# SYSCTRL register map
Vendor: Texas Instruments
Peripheral module from a debugger description file (folder UCD3138R032RJA).
Registers are 32-bit, read-write, no defined reset value unless marked. A register's access mark holds for its fields unless they carry their own. Offsets are as the file gives them; lines under a group give offsets from that group; [hi:lo] are bit positions; {n}, {i} and the like mark numbered series; 'fields as' and 'values as' point back to an identical list; <NAME> marks a mode.

## SYSCTRL
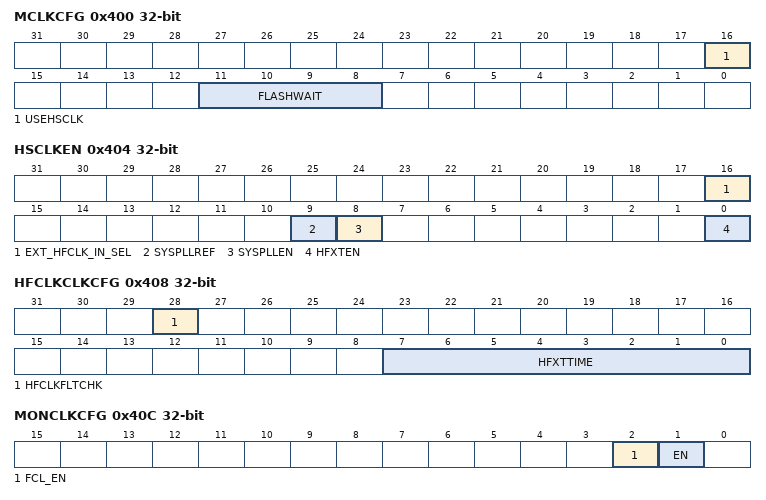
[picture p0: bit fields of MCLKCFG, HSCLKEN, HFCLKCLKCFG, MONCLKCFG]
0x400 MCLKCFG — Configuration related to MCLK
  [16] USEHSCLK — High Speed Clock Selected for MCLK (HFCLK, PLL,...)
    0=DISABLE; 1=ENABLE
  [11:8] FLASHWAIT — Flash wait states when using a high speed clock source - HFCLK or PLL
0x404 HSCLKEN — High Speed Clock Configuration
  [16] EXT_HFCLK_IN_SEL — Use External Pin as High Frequency Oscillator Source(HFCLK)
    0=DISABLE; 1=ENABLE
  [9] SYSPLLREF — System PLL Reference Clock Source 0: SYSOSC, 1:HFCLK
    0=SYSOSC; 1=HFCLK
  [8] SYSPLLEN — Enable the SYSTEM PLL
    0=DISABLE; 1=ENABLE
  [0] HFXTEN — Enable the HFXT Crystal
    0=DISABLE; 1=ENABLE
0x408 HFCLKCLKCFG — High Frequency OSC Clock Configuration
  [28] HFCLKFLTCHK — Check for stuck fault on HFCLK related pins
    0=DISABLE; 1=ENABLE
  [7:0] HFXTTIME — HFXT startup time in 64 usec resolution
0x40C MONCLKCFG — Low Frequency Monitor Clock Configuration
  [2] FCL_EN — FCL enable
    0=DISABLE; 1=ENABLE
  [1] EN — Monitor cloclk enable
    0=DISABLE; 1=ENABLE
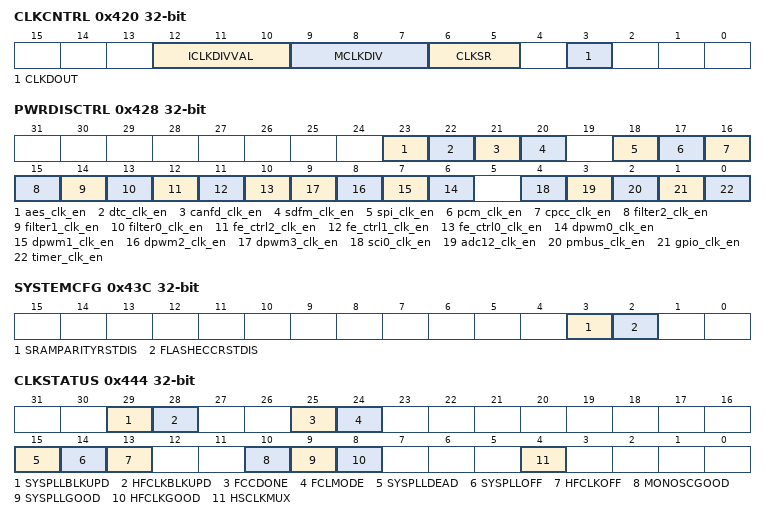
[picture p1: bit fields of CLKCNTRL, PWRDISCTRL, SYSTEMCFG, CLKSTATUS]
0x420 CLKCNTRL — General Clock Configuration
  [12:10] ICLKDIVVAL — ICLK Div ratio
    0=DIV1 (ICLK is MCLK div); 1=DIV2 (ICLK is MCLK div 2); 2=DIV4 (ICLK is MCLK div 4); 3=DIV8 (ICLK is MCLK div 8); 4=DIV16 (ICLK is MCLK div 16); 5=DIV16_X1 (ICLK is MCLK div 16); 6=DIV16_X2 (ICLK is MCLK div 16); 7=DIV16_X3 (ICLK is MCLK div 16)
  [9:7] MCLKDIV — MCLK divide ratio
    0=DIV1 (MCLK is MCLK div); 1=DIV2 (MCLK is MCLK div 2); 2=DIV4 (MCLK is MCLK div 4); 3=DIV8 (MCLK is MCLK div 8); 4=DIV16 (MCLK is MCLK div 16); 5=DIV16_X1 (MCLK is MCLK div 16); 6=DIV32 (MCLK is MCLK div 32); 7=DIV32_X1 (MCLK is MCLK div 32)
  [6:5] CLKSR — These bits control the source/function of CLKOUT
    0=CLKOUT (CLKSR is CLKOUT); 1=ICLK (CLKSR is ICLK); 2=MCLK (CLKSR is MCLK); 3=ICLKDIV4 (CLKSR is ICLK div 4)
  [3] CLKDOUT — This pin represents the output value of CLKOUT
    0=LOWLOGIC; 1=HIGHLOGIC
0x428 PWRDISCTRL — Powe control by CLock enable
  [all] fields
    0=NOTAVAILABLE; 1=AVAILABLE
  [23] aes_clk_en — clock enable
  [22] dtc_clk_en — clock enable
  [21] canfd_clk_en — clock enable
  [20] sdfm_clk_en — clock enable
  [18] spi_clk_en — clock enable
  [17] pcm_clk_en — clock enable
  [16] cpcc_clk_en — clock enable
  [15] filter2_clk_en — clock enable
  [14] filter1_clk_en — clock enable
  [13] filter0_clk_en — clock enable
  [12] fe_ctrl2_clk_en — clock enable
  [11] fe_ctrl1_clk_en — clock enable
  [10] fe_ctrl0_clk_en — clock enable
  [n+6] dpwm{n}_clk_en (n=0..3) — clock enable
  [4] sci0_clk_en — clock enable
  [3] adc12_clk_en — clock enable
  [2] pmbus_clk_en — clock enable
  [1] gpio_clk_en — clock enable
  [0] timer_clk_en — clock enable
0x43C SYSTEMCFG — System configuration for reset
  [3] SRAMPARITYRSTDIS — 0: SRAM Parity Double Error will issue System Reset 1: Reset is disable but sysstatus will be provided (default)
    0=FALSE; 1=TRUE
  [2] FLASHECCRSTDIS — 0: Flash ECC Double Error will issue System Reset 1: Reset is disable but sysstatus will be provided (default)
    0=FALSE; 1=TRUE
0x440 WRITELOCK — SYSOSC Trim Values specified by user
  [0] ACTIVE — LOCK configuration MMRs from write
    0=ENABLE (Allow Writes to Lockable MMRs); 1=DISABLE (Disallow Writes to Lockable MMRs)
0x444 CLKSTATUS ro — Useful debug status of clock selections
  [29] SYSPLLBLKUPD — Writes to SYSPLLCFG0-1, SYSPLLPARAM0-1 are blocked
    0=FALSE; 1=TRUE
  [28] HFCLKBLKUPD — Writes to HFCLKCLKCFG are blocked
    0=FALSE; 1=TRUE
  [25] FCCDONE — SYSOSC FCC DONE
    0=DISABLED; 1=ENABLED
  [24] FCLMODE — SYSOSC FCL MODE ON
    0=DISABLED; 1=ENABLED
  [15] SYSPLLDEAD — SYSPLLDEAD is set by hardware if the selected source for HSCLK was started but did not start successfully.
    0=FALSE (The HSCLK source was not started or started correctly); 1=TRUE (The HSCLK source did not start correctly)
  [14] SYSPLLOFF — SYSPLL is OFF or DEAD
    0=FALSE; 1=TRUE
  [13] HFCLKOFF — HFCLKs is OFF or DEAD
    0=FALSE; 1=TRUE
  [10] MONOSCGOOD — MONOSC ON
    0=FALSE; 1=TRUE
  [9] SYSPLLGOOD — SYSTEM PLL ON
    0=FALSE; 1=TRUE
  [8] HFCLKGOOD — High Frequency Clock ON
    0=FALSE; 1=TRUE
  [4] HSCLKMUX — High Speed Clock Selected for MCLK (HFCLK, PLL,...)
    0=SYSOSC; 1=HSCLK
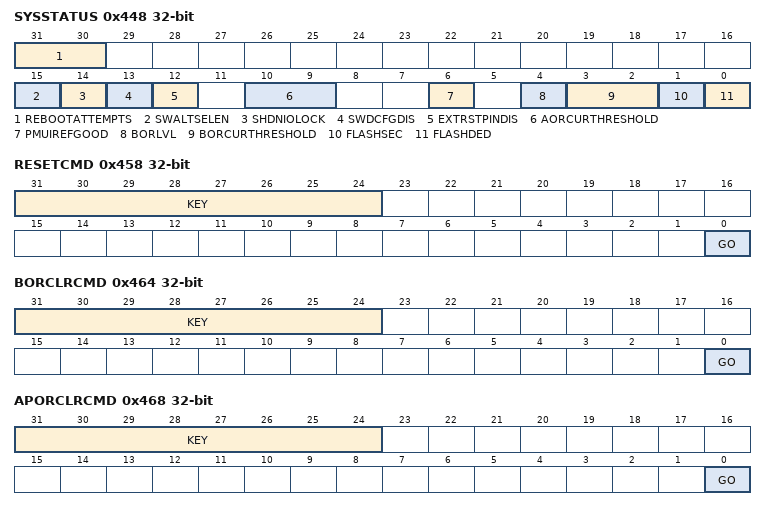
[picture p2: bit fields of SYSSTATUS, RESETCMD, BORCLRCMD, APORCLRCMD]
0x448 SYSSTATUS ro — Useful System Status Data
  [31:30] REBOOTATTEMPTS — REBOOTATTEMPTS indicates the number of boot attempts taken before the user application starts.
  [15] SWALTSELEN — SWD alternate pin selection
    0=FALSE; 1=TRUE
  [14] SHDNIOLOCK — SHDNIOLOCK indicates when IO is locked due to SHUTDOWN
    0=FALSE (IO IS NOT Locked due to SHUTDOWN); 1=TRUE (IO IS Locked due to SHUTDOWN)
  [13] SWDCFGDIS — SWDCFGDIS indicates when user has disabled the use of SWD Port
    0=FALSE (SWD Port Enabled); 1=TRUE (SWD Port Disabled)
  [12] EXTRSTPINDIS — External reset pin disable status
    0=FALSE; 1=TRUE
  [10:9] AORCURTHRESHOLD — APORCURTHRESHOLD indicates the active APOR reset supply monitor configuration.
    0=APORMIN (Default minimum threshold; a APOR0- violation triggers a APOR); 1=APORLEVEL1 (A APOR1- violation generates a APORLVL interrupt); 2=APORLEVEL2 (A APOR2- violation generates a APORLVL interrupt); 3=APORLEVEL3 (A APOR3- violation generates a APORLVL interrupt)
  [6] PMUIREFGOOD — PMU IFREF GOOD
    0=FALSE; 1=TRUE
  [4] BORLVL — BOR LEVEL STATUS Indicator
    0=FALSE; 1=TRUE
  [3:2] BORCURTHRESHOLD — BORCURTHRESHOLD indicates the active brown-out reset supply monitor configuration.
    0=BORMIN (Default minimum threshold; a BOR0- violation triggers a BOR); 1=BORLEVEL1 (A BOR1- violation generates a BORLVL interrupt); 2=BORLEVEL2 (A BOR2- violation generates a BORLVL interrupt); 3=BORLEVEL3 (A BOR3- violation generates a BORLVL interrupt)
  [1] FLASHSEC — Single Error Correction on Flash
    0=FALSE; 1=TRUE
  [0] FLASHDED — Double Error Detect on Flash
    0=FALSE; 1=TRUE
0x44C DEDERRADDR ro — Memory DED Address
  [31:0] ADDR — Address of MEMORY DED Error.
0x450 RSTCAUSE ro — Reset cause
  [4:0] ID — ID is a read-to-clear field which indicates the lowest level reset cause since the last read.
    0=NORST (No reset since last read); 1=PORHWFAIL (POR- violation, SHUTDNSTOREx or PMU trim parity fault); 2=REFCLKFAIL; 3=PORSW (Software triggered POR); 4=BORSUPPLY (BOR0- violation); 8=BOOTNONPMUPARITY (Non-PMU trim parity fault); 9=BOOTCLKFAIL (PLL Fatal clock failure); 12=BOOTEXNRST (NRST triggered BOOTRST (<1s hold)); 13=BOOTSW (Software triggered BOOTRST); 16=FLASHDED; 17=SRAMDED; 18=CPULOCK (CPU lock up condition); 19=DEBUGSS (DebugSS reset); 20=CPURESET; 21=ILLEGAL (ILLEGAL ACCESS)
0x454 RESETLEVEL — Reset level for application-triggered reset command
  [2:0] LEVEL — LEVEL is used to specify the type of reset to be issued when RESETCMD is set to generate a software triggered reset.
    1=BOOT (Issue a BOOTRST (CPU, peripherals, and boot configuration routine)); 3=POR (Issue a power-on reset (POR))
0x458 RESETCMD wo — Execute Reset Command
  [31:24] KEY — Must have KEY==0xE4(228) for write
    228=VALUE (Issue Reset)
  [0] GO — Execute Reset defined in RESETLEVEL
    1=TRUE (Issue Reset)
0x45C BORRSTDIS — BOR Reset Disable register
  [31] RSTDISABLE — BORRSTDIS specifies whether a BOR Event will trigger a BOR Reset or not.
    0=BORNRST (BOR Event will not Trigger a BOR RST); 0=BORRST (BOR Event will Trigger a BOR RST)
0x464 BORCLRCMD wo — Set the BOR threshold
  [31:24] KEY — The key value of C7h (199) must be written to KEY together with GO to trigger the clear and BOR threshold change.
    199=VALUE (Issue clear)
  [0] GO — GO clears any prior BOR violation status indications and attempts to change the active BOR mode to that specified in the LEVEL field of the BORTHRESHOLD register.
    1=TRUE (Issue clear)
0x468 APORCLRCMD wo — Set the APOR threshold
  [31:24] KEY — The key value of C8h (199) must be written to KEY together with GO to trigger the clear and APOR threshold change.
    200=VALUE (Issue clear)
  [0] GO — GO clears any prior APOR violation status indications and attempts to change the active APOR mode to that specified in the LEVEL field of the APORTHRESHOLD register.
    1=TRUE (Issue clear)
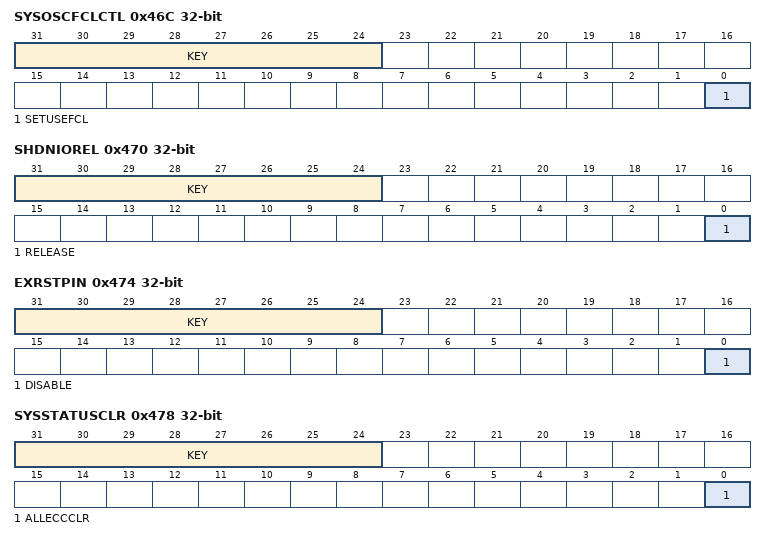
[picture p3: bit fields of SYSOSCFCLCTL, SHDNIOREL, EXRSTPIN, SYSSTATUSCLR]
0x46C SYSOSCFCLCTL wo — SYSOSC Frequency Control Loop with External Resistor
  [31:24] KEY — Must have KEY==0x2A(42) for write
    42=VALUE (Issue Command)
  [0] SETUSEFCL — Use Freq Control Loop
    1=TRUE (Set FCL Control)
0x470 SHDNIOREL wo — Shutdown IO Release Command
  [31:24] KEY — Must have KEY==0x4F(79) for write
    79=VALUE (Issue Command)
  [0] RELEASE — Release IO after Shutdown
    1=TRUE (Release IO after SHUTDOWN Exit)
0x474 EXRSTPIN wo — Disable use of external Reset Pin
  [31:24] KEY — Must have KEY==0x1E(30) for write
    30=VALUE (Issue Command)
  [0] DISABLE — Disable External Reset
    0=FALSE; 1=TRUE (Disable External Reset)
0x478 SYSSTATUSCLR wo — Clear sticky bits of SYSSTATUS
  [31:24] KEY — Must have KEY==0xCE(206) for write
    206=VALUE (Issue Command)
  [0] ALLECCCLR — Clear ALL ECC related SYSSTATUS indicators
    1=CLEAR (Clear ECC state)
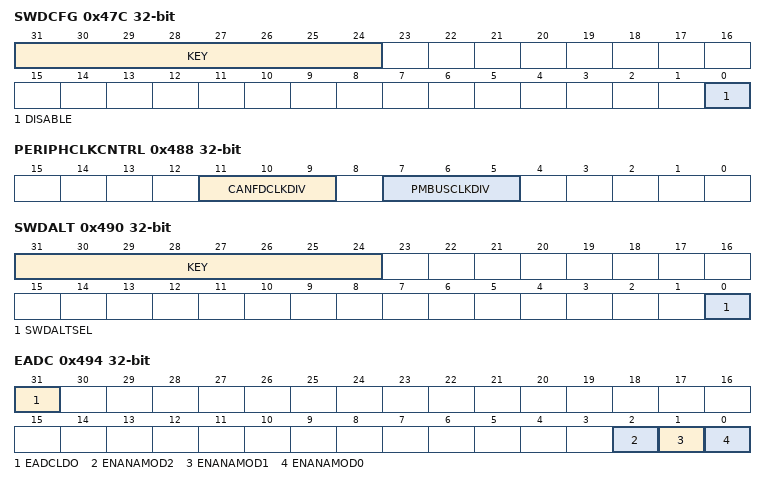
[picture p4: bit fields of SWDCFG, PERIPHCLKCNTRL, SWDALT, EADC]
0x47C SWDCFG wo — Disable SWD
  [31:24] KEY — Must have KEY==0x62(98) for write
    98=VALUE (Issue Command)
  [0] DISABLE — Set DISABLE to disable the SWD function on SWD pins, allowing the SWD pins to be used as GPIO.
    1=TRUE (Disable SWD function on SWD pins)
0x488 PERIPHCLKCNTRL — Peripheral Clock Configuration
  [11:9] CANFDCLKDIV — CANFD Clock divide ratio
    0=DIV1 (Divide ICLK by 1); 1=DIV2 (Divide ICLK by 2); 2=DIV4 (Divide ICLK by 4); 3=DIV8 (Divide ICLK by 8); 4=DIV16 (Divide ICLK by 8); 5=DIV16_X1 (Divide ICLK by 8); 6=DIV32 (Divide ICLK by 8); 7=DIV32_X1 (Divide ICLK by 8)
  [7:5] PMBUSCLKDIV — PMBUS Clock divide ratio
    values as CANFDCLKDIV
0x48C PCLKPRESCALER
  [0] PCLK_PRESCALER_DIVVAL — This determines the division value for PCLK
    0=DIV_BY_1; 1=DIV_BY_2
0x490 SWDALT wo — SWD Alternate pin selection
  [31:24] KEY — Must have KEY==0x62(98) for write
    98=VALUE (Issue Command)
  [0] SWDALTSEL — Alternal pin selection for SWDIO
    0=FALSE (PAD14 is SWDIO); 1=TRUE (PAD16 is SWDIO)
0x494 EADC — EADC control pins
  [31] EADCLDO — EADC LDO disdable pin
    1=TRUE (Disable the ADC LDO); 0=FALSE (Not disable the ADC LDO)
  [2] ENANAMOD2 — EADC EN anamod inst 2
    1=TRUE (Enable the ANAMOD 2); 0=FALSE (Disable the ANAMOD 2)
  [1] ENANAMOD1 — EADC EN anamod inst 1
    1=TRUE (Enable the ANAMOD 1); 0=FALSE (Disable the ANAMOD 1)
  [0] ENANAMOD0 — EADC EN anamod inst 0
    1=TRUE (Enable the ANAMOD 0); 0=FALSE (Disable the ANAMOD 0)
0x800 LIFECYCLE — Device Lifecycle
  [7:0] VALUE — Device Lifecycle set by BOOTCODE READY=0x69(105), ATTEST=0x55(85), PREPROBE=0x96(150)
    105=PREPROBE (Device in Pre Probe State); 150=READY (Device in Product Mode); 85=ATTEST (Device in TI Test Mode)
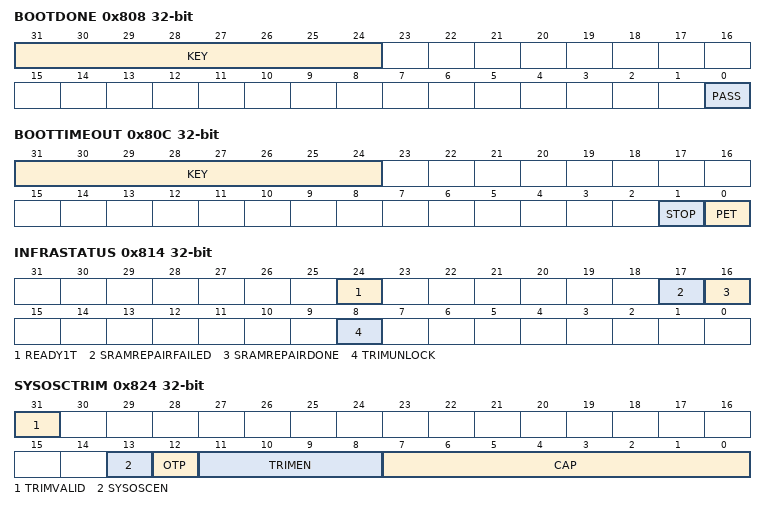
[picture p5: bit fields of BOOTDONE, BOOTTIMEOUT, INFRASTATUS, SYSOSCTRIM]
0x808 BOOTDONE wo — BOOTCODE PASS
  [31:24] KEY — Must have KEY==0xCA(202) for write
    202=VALUE (Issue Reset)
  [0] PASS — BOOTCODE writes 1 for PASS, left unwritten a timeout will occur if not blocked
    1=TRUE (BOOTCODE PASS)
0x80C BOOTTIMEOUT wo — BOOT TIMEOUT Control
  [31:24] KEY — Must have KEY==0x35(53) for write
    53=VALUE (Issue Reset)
  [1] STOP — BOOTCODE writes 1 for STOPPING BOOT TIMEOUT Counter
    1=TRUE (STOP Bootcode Timeout Counter)
  [0] PET — BOOTCODE writes 1 for reloading BOOT TIMEOUT Counter
    1=TRUE (Restart Bootcode Timeout Counter)
0x810 BCTRIMUNLOCK wo — BootCode TRIM Unlock
  [31:0] KEY — BootCode TRIM Unlock Signiture: 0xE1BE41F1
    0xE1BE41F1=VALUE (Issue Reset)
0x814 INFRASTATUS ro — Infrastructure Status
  [24] READY1T — Flash 1T Read mode is available
  [17] SRAMREPAIRFAILED — SRAM repair has failed
  [16] SRAMREPAIRDONE — SRAM repair is completed or not supported on this SOC
  [8] TRIMUNLOCK — TRIM MMRs are UNLOCKED
0x818 BOOTDIAG — 32 bit boot diagnostic to Debugss
  [31:0] BOOTSTATUS
0x81C INFRASTATUS1 ro — Infrastructure Status 2
  [0] CRPAD — Customer Return Pad
0x820 JTAGUSERCODE
  [31:0] DATA — JTAG USERCODE for Debugger
0x824 SYSOSCTRIM — SYSOSC Trim Values for frequency when change from disable to enable, generally 32MHz
  [31] TRIMVALID — TRIM Data Valid- used to trigger FSM
  [13] SYSOSCEN — SYSOSC enable
  [12] OTP — otp - tie high
  [11:8] TRIMEN — Trim en - tie low
  [7:0] CAP — CAP TRIM - Changes per frequency target
{0x828+4i} PMUTRIM{i} (i=0..6)
  [9:0] DATA — SEE PMU definition for usage
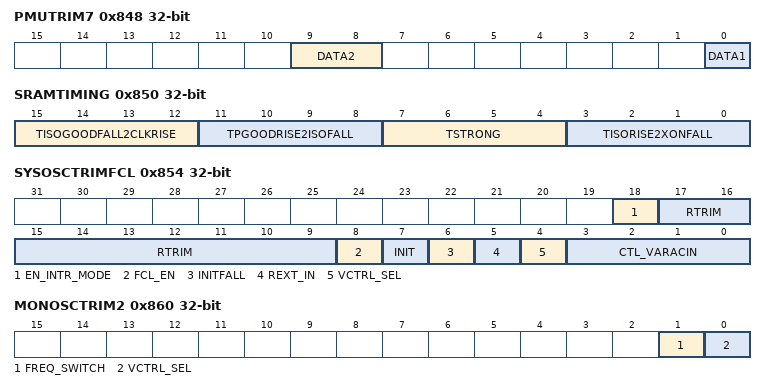
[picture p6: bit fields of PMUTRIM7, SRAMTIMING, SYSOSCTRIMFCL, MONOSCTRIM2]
0x848 PMUTRIM7
  [9:8] DATA2 — SEE PMU definition for usage
  [0] DATA1 — SEE PMU definition for usage
0x84C SRAMREPAIR — $brname sram Repair
  [13:0] DATA — Repair Bits
0x850 SRAMTIMING — SRAM timing MMR for ESRAM controller, based on 4MHz
  [15:12] TISOGOODFALL2CLKRISE — ISO GOOD FALL to CLKRISE, spec 250ns (boot 500ns)
  [11:8] TPGOODRISE2ISOFALL — PGOOD RISE to ISO FALL, spec 750ns (boot 1500ns)
  [7:4] TSTRONG — Driver Weak to Stong timing, spec 1000ns (boot 1500ns)
  [3:0] TISORISE2XONFALL — ISO Rise to any ON FALL, spec 500ns (boot 750ns)
0x854 SYSOSCTRIMFCL — SYSOSC Trim Values for frequency when change from disable to enable, generally 32MHz
  [18] EN_INTR_MODE — 1- enable internal R mode for FCL loop
  [17:9] RTRIM — sysosc Rlad trimming (9bits)
  [8] FCL_EN — 1-enable frequency control loop of sysosc
  [7] INIT — 1- precharge path cutoff when FCL_en=0
  [6] INITFALL — 1- allows to FCL mode to power up only after precharge
  [5] REXT_IN — 1-enable external R mode for FCL loop
  [4] VCTRL_SEL — 1- sets the vctrl from amp instead of divider 0- cuts off Res div when 0
  [3:0] CTL_VARACIN — default-0100 (select varactor bank)
0x858 MONOSCTRIM0 — MONOSC TRIM 1 values
  [31:0] MONCLKTRIM0 — Monitor clock Trim
0x85C MONOSCTRIM1 — MONOSC TRIM 2 values
  [31:0] MONCLKTRIM0 — Monitor clock Trim
0x860 MONOSCTRIM2 — MONOSC TRIM 3 values
  [1] FREQ_SWITCH — Frequency switch
    0=DISABLE; 1=ENABLE
  [0] VCTRL_SEL — Voltage control sel
    0=DISABLE (Voltage control is not selected); 1=Enable (Voltage control is selected)
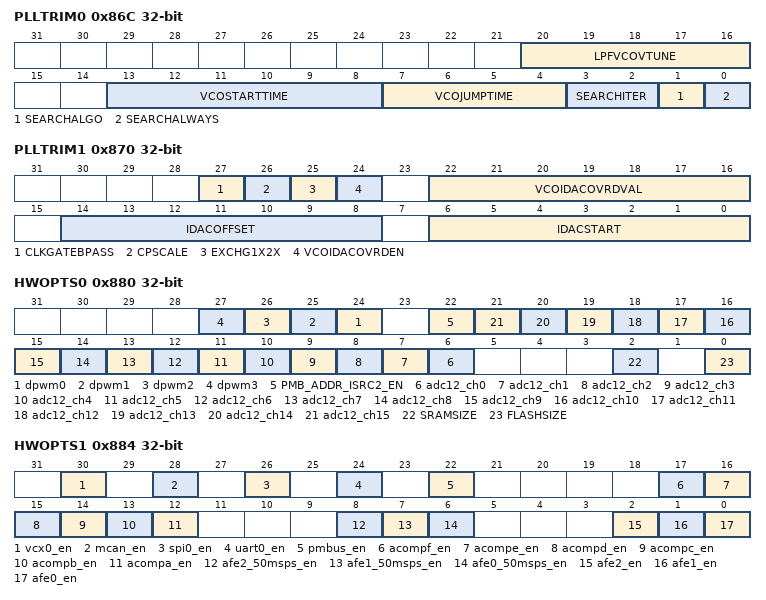
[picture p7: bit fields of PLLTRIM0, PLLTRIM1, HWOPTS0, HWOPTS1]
0x86C PLLTRIM0 — PLL TRIM and Override
  [20:16] LPFVCOVTUNE — LPF VCOVTUNE NOM Value
  [13:8] VCOSTARTTIME — VCO Start Settling Time in SYSOSC BASE clocks generally 32MHz - this comes before STARTTIME-STARTTIMELP
  [7:4] VCOJUMPTIME — VCO Freq Jump Settling Time
  [3:2] SEARCHITER — Search iterations to perform
    0=OneIteration; 1=TwoIteration; 2=ThreeIteration; 3=FourIteration
  [1] SEARCHALGO — Select Search Mode Algorithm
    0=ALG1; 1=ALG2
  [0] SEARCHALWAYS — Force Freq Search to ALWAYS be performed
    0=DISABLE; 1=ENABLE
0x870 PLLTRIM1 — PLL TRIM and Override
  [27] CLKGATEBPASS — Clock Gating Bypass added to SPARE MMR bit 1 port
    0=DISABLE; 1=ENABLE
  [26] CPSCALE — CP Scale added to SPARE MMR bit 0 port
    0=DISABLE; 1=ENABLE
  [25] EXCHG1X2X — Exchange 1X and 2X clock paths - Experimental
    0=DISABLE; 1=ENABLE
  [24] VCOIDACOVRDEN — VCO Feq IDAC mcode override enable
    0=DISABLE; 1=ENABLE
  [22:16] VCOIDACOVRDVAL — VCO Feq IDAC mcode override val
  [14:8] IDACOFFSET — IDAC Offset Value
  [6:0] IDACSTART — IDAC Start Value
0x874 MISCTRIM — Various Small TRIM
  [2:0] PMUSMPLMODE — PMU REF/BOR Sample Periode TRIM for STANDBY Mode
    0=SMPL8MS (Sample Periode is 8ms); 1=SMPL16MS (Sample Periode is 16ms); 2=SMPL32MS (Sample Periode is 32ms); 3=SMPL48MS (Sample Periode is 48ms); 4=SMPL64MS (Sample Periode is 64ms); 5=SMPL80MS (Sample Periode is 80ms); 6=SMPL100MS (Sample Periode is 100ms); 7=SMPL125MS (Sample Periode is 125ms)
0x880 HWOPTS0 — IP Available Paper Spin
  [all] fields
    0=NOTAVAILABLE; 1=AVAILABLE
  [n+24] dpwm{n} (n=0..3) — Peripheral Instance Available
  [22] PMB_ADDR_ISRC2_EN — Peripheral Instance Available
  [n+6] adc12_ch{n} (n=0..15) — Peripheral Instance Available
  [2] SRAMSIZE — Peripheral Instance Available
  [0] FLASHSIZE — Peripheral Instance Available
0x884 HWOPTS1 — IP Available Paper Spin
  [all] fields
    0=NOTAVAILABLE; 1=AVAILABLE
  [30] vcx0_en — Peripheral Instance Available
  [28] mcan_en — Peripheral Instance Available
  [26] spi0_en — Peripheral Instance Available
  [24] uart0_en — Peripheral Instance Available
  [22] pmbus_en — Peripheral Instance Available
  [17] acompf_en — Peripheral Instance Available
  [16] acompe_en — Peripheral Instance Available
  [15] acompd_en — Peripheral Instance Available
  [14] acompc_en — Peripheral Instance Available
  [13] acompb_en — Peripheral Instance Available
  [12] acompa_en — Peripheral Instance Available
  [8] afe2_50msps_en — Peripheral Instance Available
  [7] afe1_50msps_en — Peripheral Instance Available
  [6] afe0_50msps_en — Peripheral Instance Available
  [2] afe2_en — Peripheral Instance Available
  [1] afe1_en — Peripheral Instance Available
  [0] afe0_en — Peripheral Instance Available
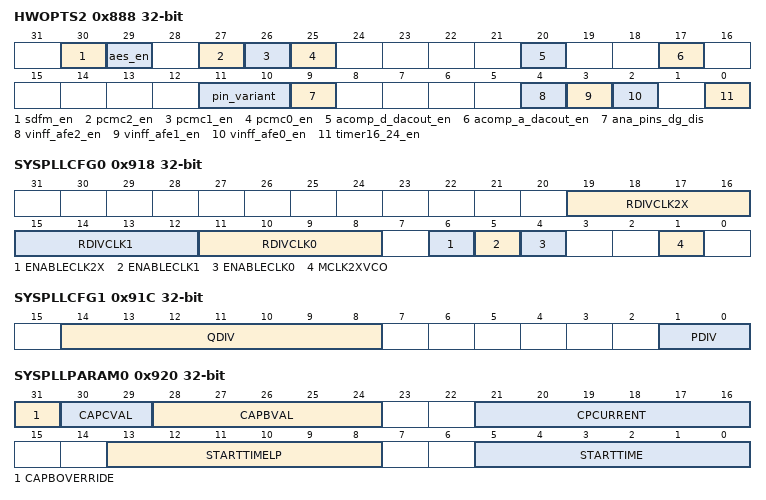
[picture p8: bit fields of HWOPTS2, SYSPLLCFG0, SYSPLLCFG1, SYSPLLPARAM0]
0x888 HWOPTS2 — IP Available Paper Spin
  [30] sdfm_en — Enables SDFM module
    0=Disable_SDFM_Module; 1=Enable_SDFM_Module
  [29] aes_en — Peripheral Instance Available
    0=NOTAVAILABLE; 1=AVAILABLE
  [27] pcmc2_en — Peripheral Instance Available
    0=NOTAVAILABLE; 1=AVAILABLE
  [26] pcmc1_en — Peripheral Instance Available
    0=NOTAVAILABLE; 1=AVAILABLE
  [25] pcmc0_en — Peripheral Instance Available
    0=NOTAVAILABLE; 1=AVAILABLE
  [20] acomp_d_dacout_en — Peripheral Instance Available
    0=NOTAVAILABLE; 1=AVAILABLE
  [17] acomp_a_dacout_en — Peripheral Instance Available
    0=NOTAVAILABLE; 1=AVAILABLE
  [11:10] pin_variant — Controls the pin variant for IO-MUX selections in the IOC controller
    0=Variant24pin; 1=Variant32pin; 3=Variant40pin
  [9] ana_pins_dg_dis — Peripheral Instance Available
    0=NOTAVAILABLE; 1=AVAILABLE
  [4] vinff_afe2_en — Peripheral Instance Available
    0=NOTAVAILABLE; 1=AVAILABLE
  [3] vinff_afe1_en — Peripheral Instance Available
    0=NOTAVAILABLE; 1=AVAILABLE
  [2] vinff_afe0_en — Peripheral Instance Available
    0=NOTAVAILABLE; 1=AVAILABLE
  [0] timer16_24_en — Peripheral Instance Available
    0=NOTAVAILABLE; 1=AVAILABLE
0x88C TRIMCRC — FINAL 16 bit CRC of the TRIM load
  [31:0] DATA — final 16 bit CRC value
0x890 ADCLDOCNTL — ADC LDO control bits
  [14:0] DATA
0x894 ANATOPREG1 — ANATOP Regsiter 1
  [31:0] DATA — Anatop register 1
0x898 ANATOPREG2 — ANATOP Regsiter 2
  [31:0] DATA — Anatop register 2
0x89C CLKTOPREG6 — CLKTOP Regsiter 6
  [31:0] DATA — Clktop register 6
0x910 CLKTOPREG7 — CLKTOP Regsiter 7
  [31:0] DATA — Clktop register 7
0x914 CLKTOPREG8 — CLKTOP Regsiter 8
  [31:0] DATA — Clktop register 8
0x918 SYSPLLCFG0 — System PLL Configuration 0 MMR
  [19:16] RDIVCLK2X — Final Divider for CLK2X Output 1-16
  [15:12] RDIVCLK1 — Final Divider for CLK1 Output 1-16
  [11:8] RDIVCLK0 — Final Divider for CLK0 Output 1-16
  [6] ENABLECLK2X — PLL CLK2X Output enabled
    0=DISABLE; 1=ENABLE
  [5] ENABLECLK1 — PLL CLK1 Output enabled
    0=DISABLE; 1=ENABLE
  [4] ENABLECLK0 — PLL CLK0 Output enabled
    0=DISABLE; 1=ENABLE
  [1] MCLK2XVCO — Use PLL CLK2X PATH as source for MCLK
    0=DISABLE; 1=ENABLE
0x91C SYSPLLCFG1 — System PLL Configuration 1 MMR
  [14:8] QDIV — PLL Feedback Clock Divider 1-127 by 1
  [1:0] PDIV — PLL Reference Clock Divider 1,2,4,8
    0=REFDIV1 (PLL REF CLK is REF CLK); 1=REFDIV2 (PLL REF CLK is REF CLK div 2); 2=REFDIV4 (PLL REF CLK is REF CLK div 4); 3=REFDIV8 (PLL REF CLK is REF CLK div 8)
0x920 SYSPLLPARAM0 — System PLL Paramater 0 MMR --- Data from Flash Table Lookup
  [31] CAPBOVERRIDE — Override Enable For Cap B
    0=DISABLE; 1=ENABLE
  [30:29] CAPCVAL — Override Value for Cap C
  [28:24] CAPBVAL — Override Value for Cap B
  [21:16] CPCURRENT — Charge Pump Current
  [13:8] STARTTIMELP — Startup time from Low Power Exit to Locked Clock in resolution of 1usec
  [5:0] STARTTIME — Startup time from Enable to Locked Clock in resolution of 1usec
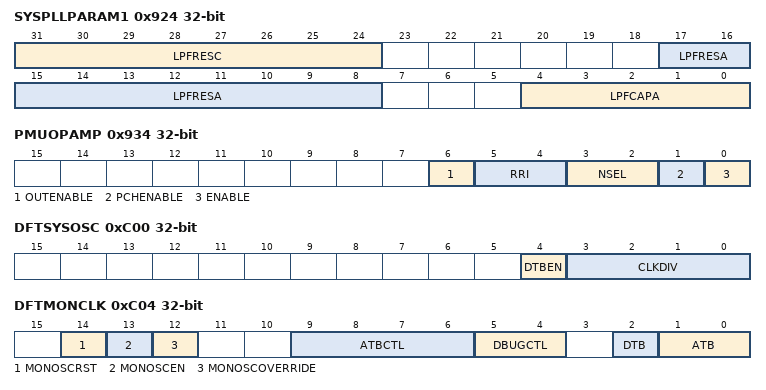
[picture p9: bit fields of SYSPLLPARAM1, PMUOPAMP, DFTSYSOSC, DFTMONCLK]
0x924 SYSPLLPARAM1 — System PLL Paramater 1 MMR --- Data from Flash Table Lookup
  [31:24] LPFRESC — Loop Filter Res C
  [17:8] LPFRESA — Loop Filter Res A
  [4:0] LPFCAPA — Loop Filter Cap A
0x928 LDOCONTROLBITS — DIG LDO control bits
  [4:0] DATA
0x92C APORTHRESHOLD — APOR Threshold Level
  [1:0] LEVEL — APOR Threshold Level 0: Full Re-boot This level is always enforced regardless of MMR seting 1-3: Generates interrupt
    0=APORMIN (Minimum allowed threshold - will force a re-boot); 1=BORLEVEL1 (BOR Level 1 -- Generates an Interupt); 2=APORLEVEL2 (BOR Level 2 -- Generates an Interupt); 3=APORLEVEL3 (BOR Level 3 -- Generates an Interupt)
0x930 BORTHRESHOLD — BOR Threshold Level
  [1:0] LEVEL — BOR Threshold Level 0: Full Re-boot This level is always enforced regardless of MMR seting 1-3: Generates interrupt
    3=BORMIN (Minimum allowed threshold - will force a re-boot)
0x934 PMUOPAMP — PMU OPAMP Control
  [6] OUTENABLE — Output To Pad Enable
    0=FALSE; 1=TRUE
  [5:4] RRI — Rail to Rail Input Mode Select
    0=MODE0 (select PMOS input pairs mode); 1=MODE1 (select NMOS input pairs mode); 2=MODE2 (select rail to rail mode); 3=MODE3 (select sample channel 0)
  [3:2] NSEL — Negative Channel Input Select
    0=SEL0 (Select buf output pad as input); 1=SEL1 (slect unbuf output pad as input); 2=SEL2 (select internal buffer output as input); 3=SEL3 (no channel selected)
  [1] PCHENABLE — Positive Channel Input Enable
    0=FALSE; 1=TRUE
  [0] ENABLE — Enable PMU OPAMP
    0=FALSE; 1=TRUE
0x938 MCANSRAMREPAIR — $brname sram Repair
  [13:0] DATA — Repair Bits
0xC00 DFTSYSOSC — DFT Control for HFXT
  [4] DTBEN — Enable DTB Structure
    0=DISABLE; 1=ENABLE
  [3:0] CLKDIV — Clock Div value for DTB
0xC04 DFTMONCLK — DFT Control for MONCLK Hard Macro
  [14] MONOSCRST — MON OSC reset
  [13] MONOSCEN — MON OSC enable
  [12] MONOSCOVERRIDE — MON OSC enable
  [9:6] ATBCTL — ATB control
  [5:4] DBUGCTL — Debug control
  [2] DTB — DTB enable
    0=DISABLE; 1=ENABLE
  [1:0] ATB — Bit1: enables buffered path, Bit0 enables unbuffered path
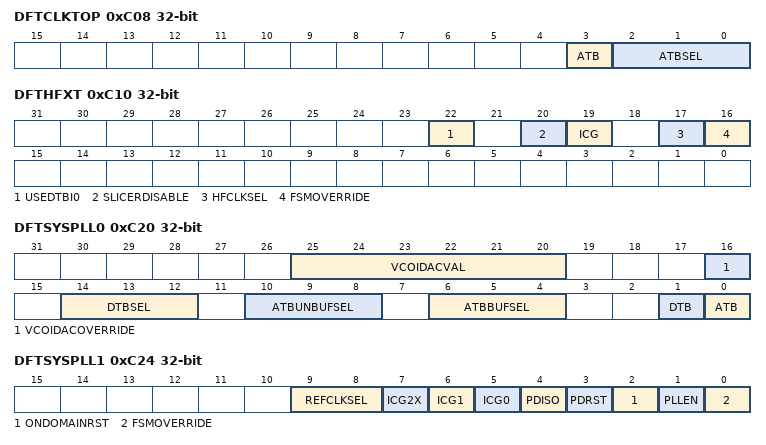
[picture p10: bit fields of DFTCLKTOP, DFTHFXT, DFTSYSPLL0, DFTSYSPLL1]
0xC08 DFTCLKTOP — DFT for CLKTOP to bring voltage reference
  [3] ATB — ATB enable
  [2:0] ATBSEL — ATB Select line
0xC10 DFTHFXT — DFT Control for HFXT
  [22] USEDTBI0 — Use DTBI[0] as the HFCLK output
    0=FALSE; 1=TRUE
  [20] SLICERDISABLE — Turn off slicer
    0=FALSE; 1=TRUE
  [19] ICG — Override Turn HFCLK related ICGs ON qualified with HFCLKSEL
    0=DISABLE; 1=ENABLE
  [17] HFCLKSEL — Use External Pin as High Frequency Oscillator Source(HFCLK)
    0=HFXT; 1=EXTHF
  [16] FSMOVERRIDE — Override outputs of HFCLK FSM
    0=DISABLE; 1=ENABLE
0xC20 DFTSYSPLL0 — DFT Control for SYSPLL
  [25:20] VCOIDACVAL — Override Value For VCO Freq Idac Code
  [16] VCOIDACOVERRIDE — Override Enable For VCO Freq Idac Code
    0=DISABLE; 1=ENABLE
  [14:12] DTBSEL — DTB Signal Select
  [10:8] ATBUNBUFSEL — ATB UnBuffered Signal Select
  [6:4] ATBBUFSEL — ATB Buffered Signal Select
  [1] DTB — Enable DTB Structure
    0=DISABLE; 1=ENABLE
  [0] ATB — Enable ATB Structure
    0=DISABLE; 1=ENABLE
0xC24 DFTSYSPLL1 — DFT Control for SYSPLL
  [9:8] REFCLKSEL — Override value to select Ref Clk
    0=SYSOSC; 1=HFCLK; 2=DTBI0
  [7] ICG2X — Override value to turn PLL ICGCLK2X ON
    0=DISABLE; 1=ENABLE
  [6] ICG1 — Override value to turn PLL ICGCLK1 ON
    0=DISABLE; 1=ENABLE
  [5] ICG0 — Override value to turn PLL ICGCLK0 ON
    0=DISABLE; 1=ENABLE
  [4] PDISO — Assert ISO PD to the hard macro
    0=DEASSERT; 1=ASSERT
  [3] PDRST — Assert RST PD to the hard macro
    0=DEASSERT; 1=ASSERT
  [2] ONDOMAINRST — Assert ONDOMAIN RST to the hard macro
    0=DEASSERT; 1=ASSERT
  [1] PLLEN — Override value for PLL ENABLE to PLL
    0=DISABLE; 1=ENABLE
  [0] FSMOVERRIDE — Override outputs of PLL FSM
    0=DISABLE; 1=ENABLE
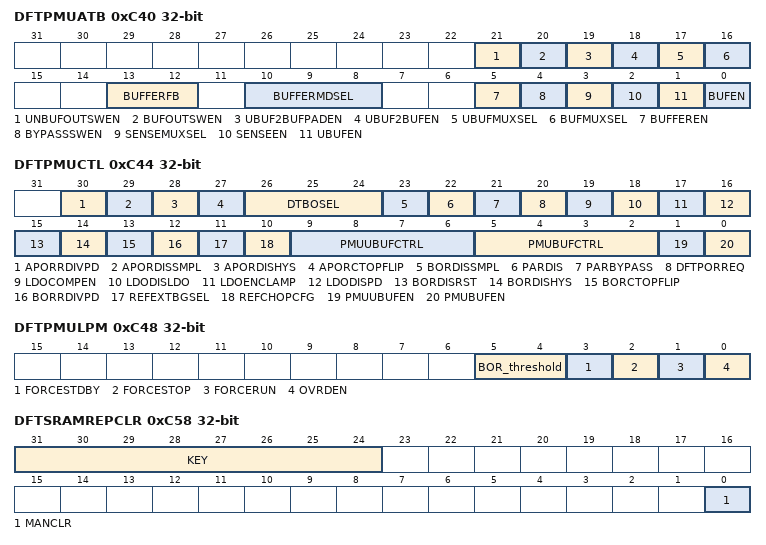
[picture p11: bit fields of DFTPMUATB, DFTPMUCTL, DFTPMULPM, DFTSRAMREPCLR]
0xC40 DFTPMUATB — DFT Control for PMU ATB
  [21] UNBUFOUTSWEN
  [20] BUFOUTSWEN
  [19] UBUF2BUFPADEN
  [18] UBUF2BUFEN
  [17] UBUFMUXSEL
  [16] BUFMUXSEL
  [13:12] BUFFERFB
  [10:8] BUFFERMDSEL
  [5] BUFFEREN
  [4] BYPASSSWEN
  [3] SENSEMUXSEL
  [2] SENSEEN
  [1] UBUFEN — ATB UnBuffered Output Enable
  [0] BUFEN — ATB Buffered Output Enable
0xC44 DFTPMUCTL — DFT Control for PMU CTL
  [30] APORRDIVPD
  [29] APORDISSMPL
  [28] APORDISHYS
  [27] APORCTOPFLIP
  [26:24] DTBOSEL
  [23] BORDISSMPL
  [22] PARDIS
  [21] PARBYPASS
  [20] DFTPORREQ
  [19] LDOCOMPEN
  [18] LDODISLDO
  [17] LDOENCLAMP
  [16] LDODISPD
  [15] BORDISRST
  [14] BORDISHYS
  [13] BORCTOPFLIP
  [12] BORRDIVPD
  [11] REFEXTBGSEL
  [10] REFCHOPCFG
  [9:6] PMUUBUFCTRL
  [5:2] PMUBUFCTRL
  [1] PMUUBUFEN — ATB UnBuffered Output Enable
  [0] PMUBUFEN — ATB Buffered Output Enable
0xC48 DFTPMULPM — DFT Control for PMU LPM
  [5:4] BOR_threshold, [3] FORCESTDBY, [2] FORCESTOP, [1] FORCERUN, [0] OVRDEN
0xC58 DFTSRAMREPCLR wo — Clear SRAM Repair Data
  [31:24] KEY — Must have KEY==0xF3(243) for write
    243=VALUE (Issue Command)
  [0] MANCLR — Send CLR to SRAM Banks
    1=TRUE
0xC5C DFTSRAMREPSHFT ro — Shift SRAM Repair Preamble Read-Only
  [29:0] DATA — SRAM Data from Shift
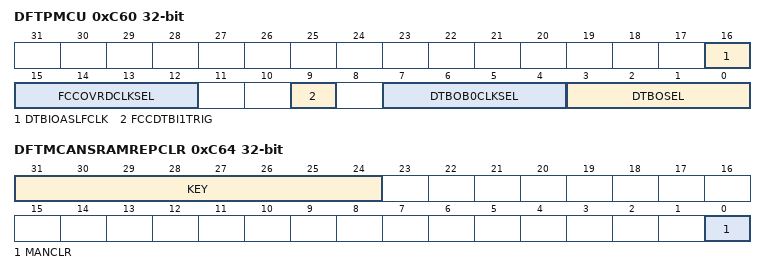
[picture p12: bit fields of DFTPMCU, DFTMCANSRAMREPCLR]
0xC60 DFTPMCU — Overall PMCU DFT Controls
  [16] DTBIOASLFCLK — Use DTBI0 as the LFCLK source
    0=DISABLE; 1=ENABLE
  [15:12] FCCOVRDCLKSEL — DFT selections for CLK source of counter
    0=FCCSELCLK; 1=DTBI0; 2=ADC0OSCLK; 3=ADC1OSCLK; 4=RAWSYSOSC (Directly from MSIP)
  [9] FCCDTBI1TRIG — Use DTBI1 as the trigger
    0=DISABLE; 1=ENABLE
  [7:4] DTBOB0CLKSEL — DFT selections for OTHERCLKS bit 0 of DTB
    0=VBST4MHZCLK; 1=PMUCHOPCLK; 2=FINALVBSTCLK; 3=FUNCEXTCLK
  [3:0] DTBOSEL — Major DTB Output Select
    0=PMU; 1=SYSPLL; 2=LFCLK; 3=OTHERCLKS; 4=SYSOSC
0xC64 DFTMCANSRAMREPCLR wo — Clear SRAM Repair Data
  fields as DFTSRAMREPCLR
0xC68 DFTMCANSRAMREPSHFT ro — Shift SRAM Repair Preamble Read-Only
  [29:0] DATA — SRAM Data from Shift
